# CH32V203G6U6 register map
Vendor: WCH; File version: 0.1.0
CPU: QingKe V4B V4B, little endian, no MPU, no FPU, vendor SysTick, 4 interrupt priority bits
Registers are 16-bit, read-write, reset 0x0 unless marked. A register's access mark holds for its fields unless they carry their own. Offsets are from the block's base; [hi:lo] are bit positions; lines under a group give offsets from that group; {n}, {i} and the like mark numbered series.

## ADC1 — 12-bit ADC unit 1 / TouchKey block
Base 0x40012400
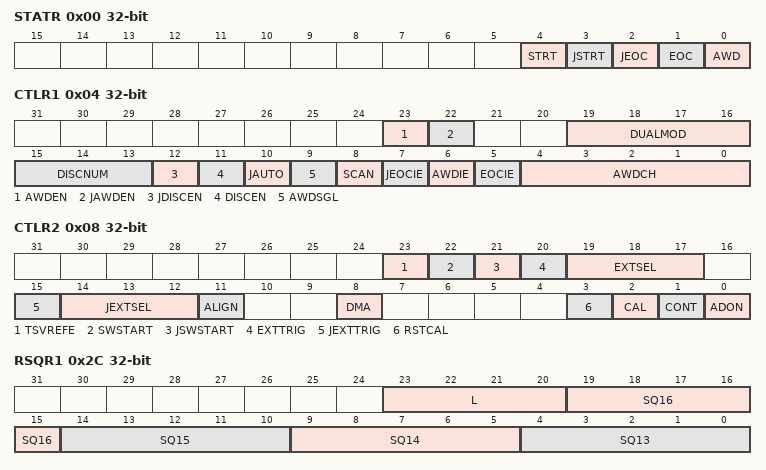
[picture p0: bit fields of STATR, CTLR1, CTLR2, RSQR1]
0x00 STATR 32-bit — status register
  [4] STRT — Regular channel start flag
  [3] JSTRT — Injected channel start flag
  [2] JEOC — Injected channel end of conversion
  [1] EOC — Regular channel end of conversion
  [0] AWD — Analog watchdog flag
0x04 CTLR1 32-bit — control register 1/TKEY_V_CTLR
  [23] AWDEN — Analog watchdog enable on regular channels
  [22] JAWDEN — Analog watchdog enable on injected channels
  [19:16] DUALMOD — Dual mode selection
  [15:13] DISCNUM — Discontinuous mode channel count
  [12] JDISCEN — Discontinuous mode on injected channels
  [11] DISCEN — Discontinuous mode on regular channels
  [10] JAUTO — Automatic injected group conversion
  [9] AWDSGL — Enable the watchdog on a single channel in scan mode
  [8] SCAN — Scan mode enable
  [7] JEOCIE — Interrupt enable for injected channels
  [6] AWDIE — Analog watchdog interrupt enable
  [5] EOCIE — Interrupt enable for EOC
  [4:0] AWDCH — Analog watchdog channel select bits
0x08 CTLR2 32-bit — control register 2
  [23] TSVREFE — Temperature sensor and VREFINT enable
  [22] SWSTART — Start conversion of regular channels
  [21] JSWSTART — Start conversion of injected channels
  [20] EXTTRIG — External trigger conversion mode for regular channels
  [19:17] EXTSEL — External event select for regular group
  [15] JEXTTRIG — External trigger conversion mode for injected channels
  [14:12] JEXTSEL — External event select for injected group
  [11] ALIGN — Data alignment
  [8] DMA — Direct memory access mode
  [3] RSTCAL — Reset calibration
  [2] CAL — A/D calibration
  [1] CONT — Continuous conversion
  [0] ADON — A/D converter ON / OFF
0x0C SAMPTR1 32-bit reset not defined — sample time register 1
  [3n-28:3n-30] SMP{n} (n=10..17)
  [3n-28:3n-30] SMP{n}_TKCG{n} (n=10..17) — Channel {n} sample time selection
0x10 SAMPTR2 32-bit reset not defined — sample time register 2
  [3n+2:3n] SMP{n} (n=0..9)
  [3n+2:3n] SMP{n}_TKCG{n} (n=0..9) — Channel {n} sample time selection
{0x10+4i} IOFR{i} 32-bit (i=1..4) — injected channel data offset register x
  [11:0] JOFFSET{i} — Data offset for injected channel x
0x24 WDHTR 32-bit — watchdog higher threshold register
  [11:0] HT — Analog watchdog higher threshold
0x28 WDLTR 32-bit — watchdog lower threshold register
  [11:0] LT — Analog watchdog lower threshold
0x2C RSQR1 32-bit — regular sequence register 1
  [23:20] L — Regular channel sequence length
  [5n-61:5n-65] SQ{n} (n=13..16) — {n}th conversion in regular sequence
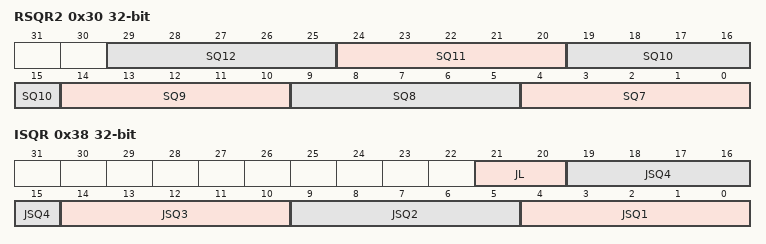
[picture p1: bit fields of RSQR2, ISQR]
0x30 RSQR2 32-bit — regular sequence register 2
  [5n-31:5n-35] SQ{n} (n=7..12) — {n}th conversion in regular sequence
0x34 RSQR3 32-bit reset not defined — regular sequence register 3;TKEY_V_CHANNEL
  [29:25] SQ6 — 6th conversion in regular sequence
  [24:20] SQ5 — 5th conversion in regular sequence
  [19:15] SQ4 — 4th conversion in regular sequence
  [14:10] SQ3 — 3rd conversion in regular sequence
  [9:5] SQ2 — 2nd conversion in regular sequence
  [4:0] SQ1
  [4:0] SQ1__CHSEL — 1st conversion in regular sequence;TKDY_V channel select
0x38 ISQR 32-bit — injected sequence register
  [21:20] JL — Injected sequence length
  [19:15] JSQ4 — 4th conversion in injected sequence
  [14:10] JSQ3 — 3rd conversion in injected sequence
  [9:5] JSQ2 — 2nd conversion in injected sequence
  [4:0] JSQ1 — 1st conversion in injected sequence
0x3C IDATAR1 32-bit reset not defined — injected data register x_Charge data offset for injected channel x
  [15:8] IDATA8_15 — Injected data
  [15:0] JDATA
  [7:0] IDATA0_7_TKCGOFFSET — Injected data_Touch key charge data offset for injected channel x
{0x38+4i} IDATAR{i} 32-bit (i=2..4) — injected data register x
  [15:0] JDATA — Injected data
0x4C RDATAR 32-bit reset not defined — regular data register_start and discharge time register
  [31:16] ADC2DATA
  [15:8] DATA8_15 — Regular data
  [15:0] DATA
  [7:0] DATA0_7_TKACT_DCG — Regular data_Touch key start and discharge time register

## ADC2 — 12-bit ADC unit 2 / TouchKey block
Base 0x40012800
Registers as ADC1; these are added or differ:
0x4C RDATAR 32-bit reset not defined — regular data register_start and discharge time register
  [31:16] ADC2DATA
  [15:8] DATA8_15 — Regular data
  [15:0] DATA
  [7:0] DATA0_7_TKACT_DCG — Regular data_Touch key start and discharge time register
